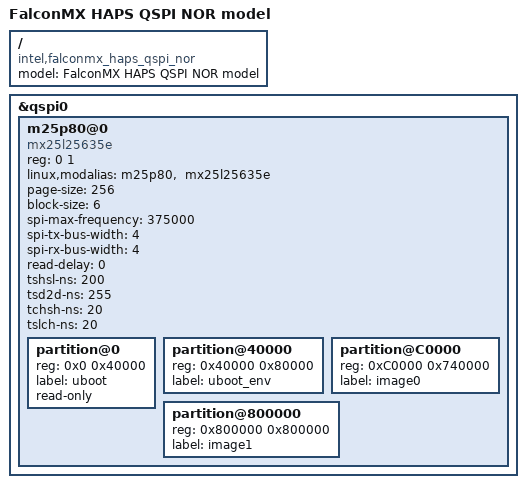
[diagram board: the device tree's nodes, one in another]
/dts-v1/;
#include "falconmx_haps.dtsi"

/ {
	model = "FalconMX HAPS QSPI NOR model";
	compatible = "intel,falconmx_haps_qspi_nor", "intel,falconmx";
};

&qspi0 {
	m25p80@0 {
		status = "okay";
		#address-cells = <1>;
		#size-cells = <1>;
		compatible = "mx25l25635e";
		reg = <0 1>;
		linux,modalias = "m25p80", " mx25l25635e";
		page-size = <256>;
		block-size = <6>; // 2^6, 64B
		spi-max-frequency = <375000>;
		spi-tx-bus-width = <4>;
		spi-rx-bus-width = <4>;
		read-delay = <0>;
		tshsl-ns = <200>;
		tsd2d-ns = <255>;
		tchsh-ns = <20>;
		tslch-ns = <20>;

		/* Basic fallback partition layout. Real partition should be
		 * defined in kernel boot parameters by uboot.
		 */
		partition@0 {
			reg = <0x0 0x40000>;
			label = "uboot";
			read-only;
		};

		partition@40000 {
			reg = <0x40000 0x80000>;
			label = "uboot_env";
		};

		partition@C0000 {
			reg = <0xC0000 0x740000>;
			label = "image0";
		};

		partition@800000 {
			reg = <0x800000 0x800000>;
			label = "image1";
		};
	};
};
